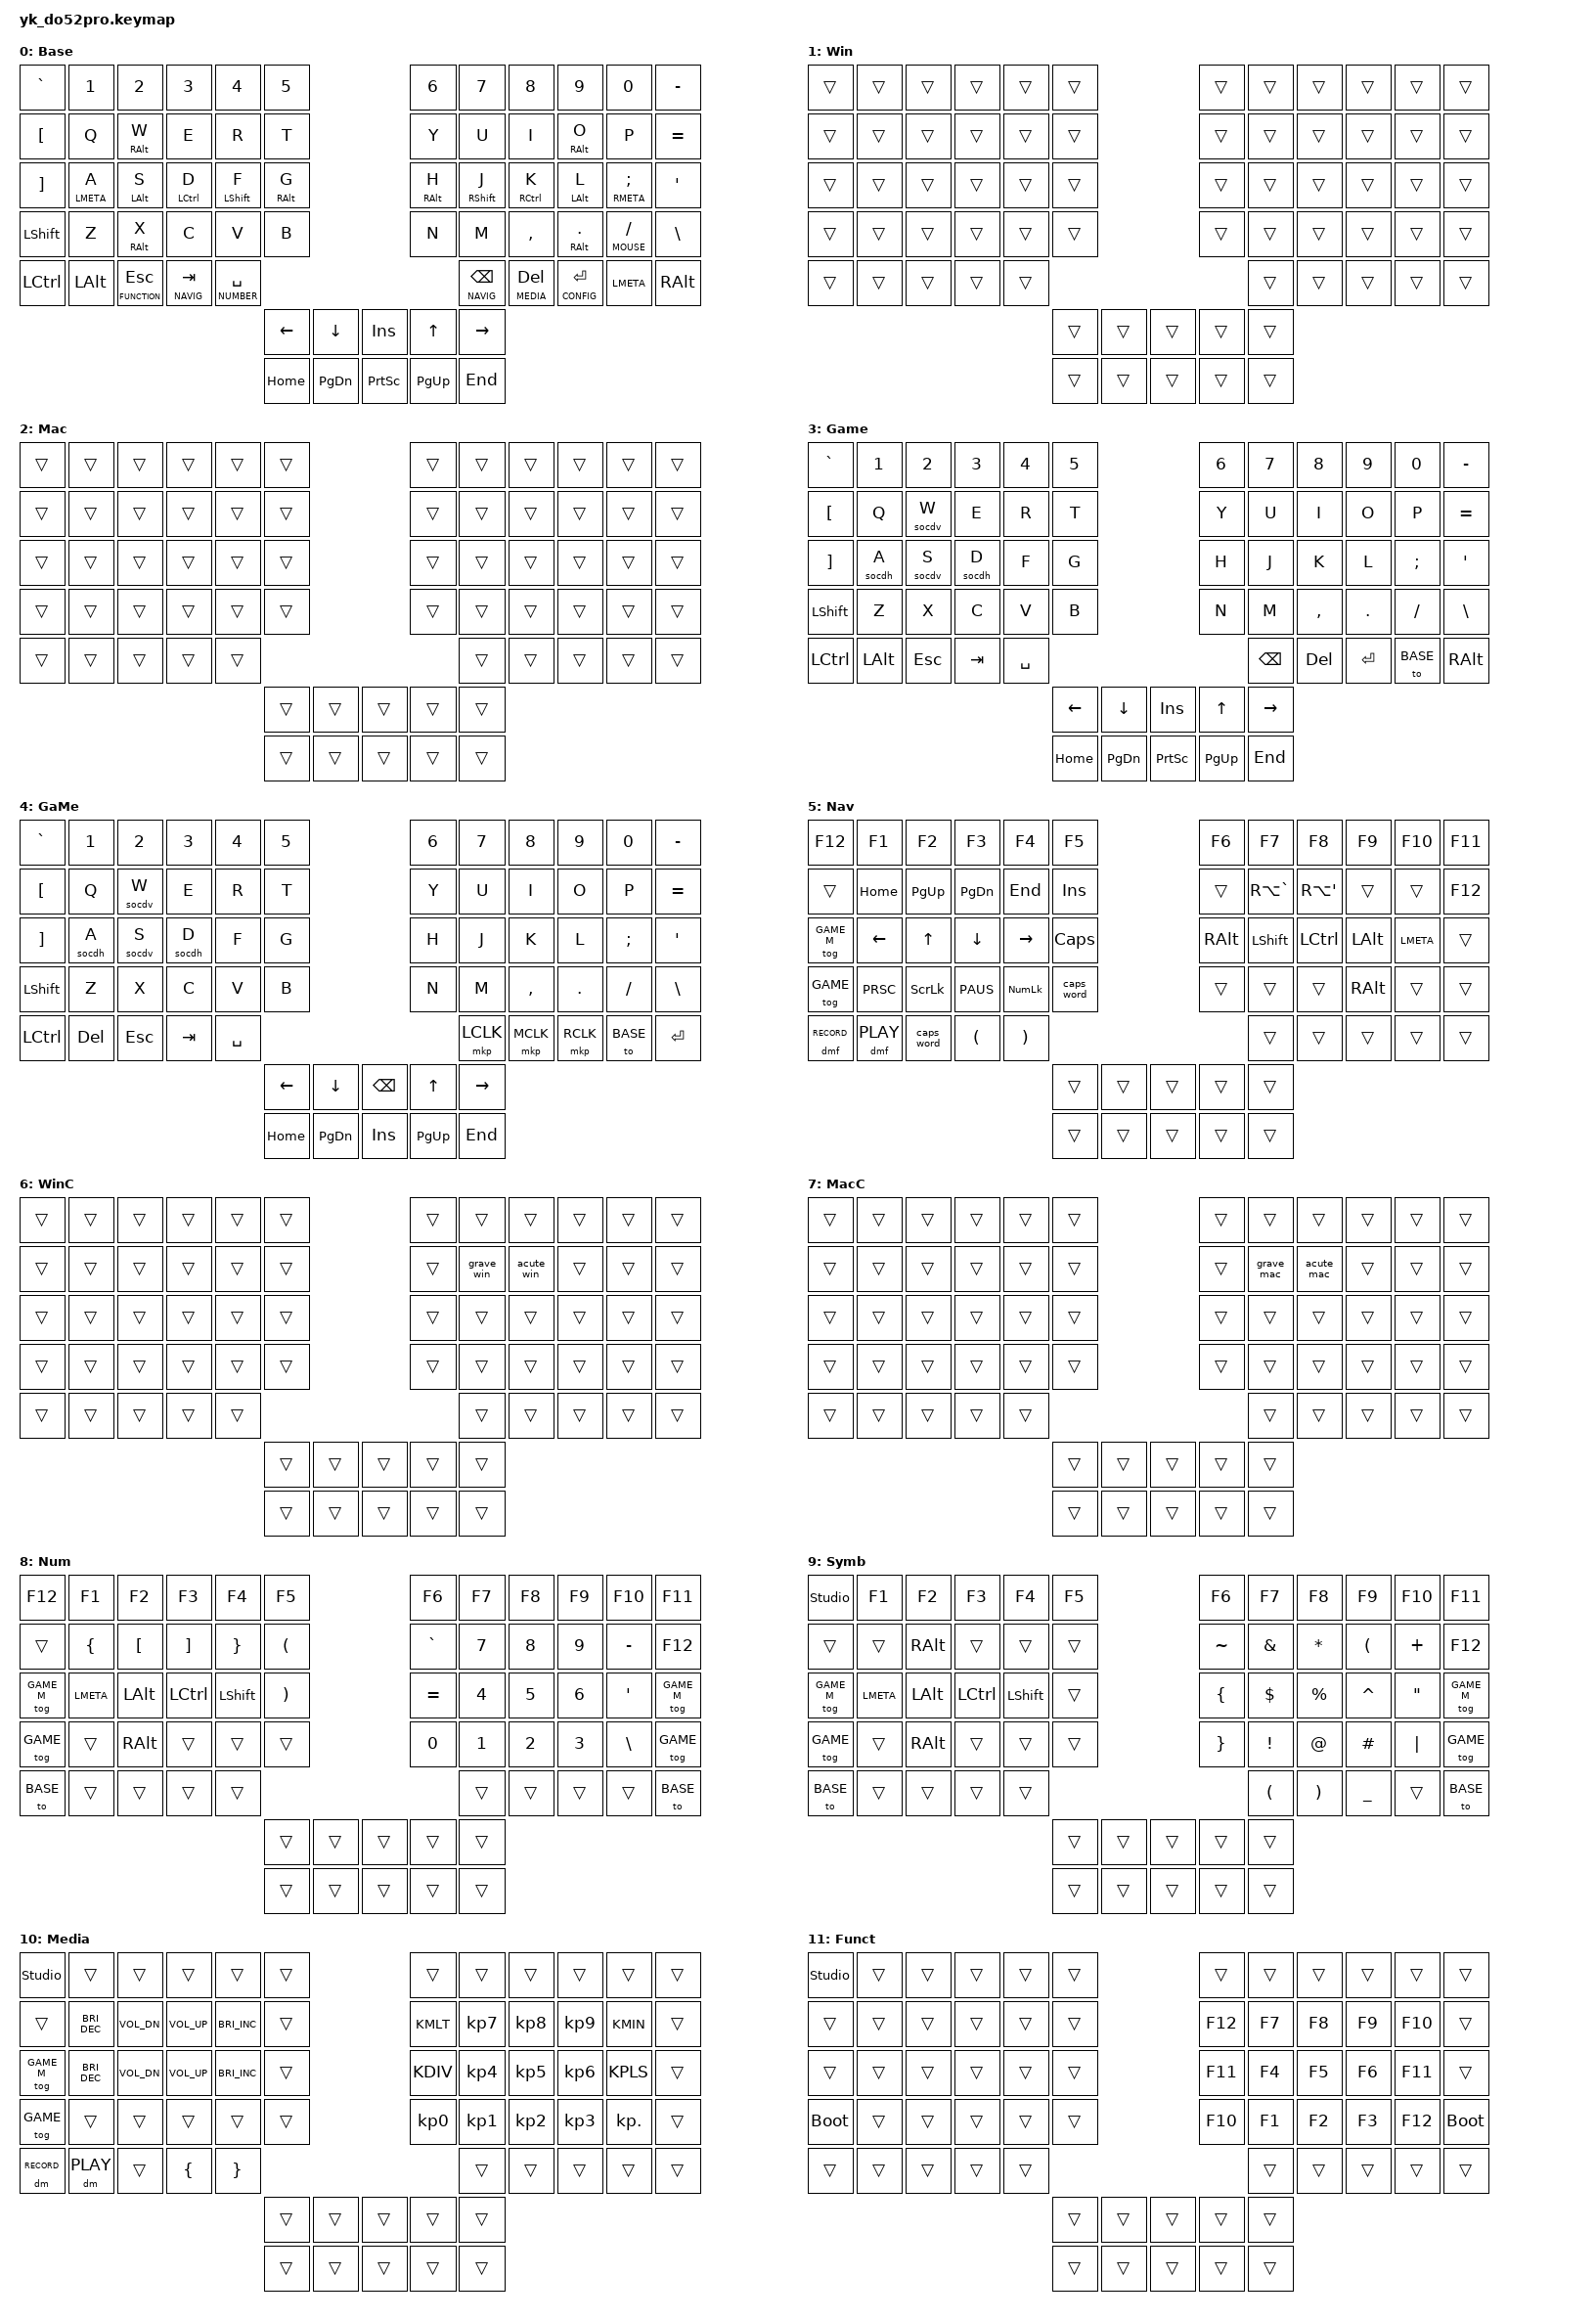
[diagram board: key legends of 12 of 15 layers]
/*
 * Copyright (c) 2020 The ZMK Contributors
 *
 * SPDX-License-Identifier: MIT
 */

#include <behaviors.dtsi>
#include <dt-bindings/zmk/keys.h>

//#include "zmk-helpers/helper.h"
#include "include/yk_do52_key.h"  
#include "include/hex_setup_macros.dtsi"                                     

#include <dt-bindings/zmk/bt.h>
#include <dt-bindings/zmk/ext_power.h>
#include <dt-bindings/zmk/outputs.h>

//#include <behaviors/battery_percentage_printer.dtsi>
#include <behaviors/socd.dtsi>
#include <dt-bindings/zmk/dynamic_macros.h>
#include "include/yk_do52pro_layers.dtsi"


/*
 * Defines to enable/disable features
 *
 * These defines allow us to conditionally enable and disable parts of the keymap config.
 *
 * For example, if we decide to build the firmware without the mouse features, we can
 * disable all the config options that rely on those forks and modules without having
 * to edit the entire keymap file manually every time.
 */

#define HAS_MOUSE_KEYS
#define HAS_MOUSE_TP

/ {
    conditional_layers {
        compatible = "zmk,conditional-layers";

        windows_accent {
            if-layers = <WIN NAVIG>;
            then-layer = <WINC>;
        };

        macos_accent {
            if-layers = <MAC NAVIG>;
            then-layer = <MACC>;
        };
    };
};


#ifdef HAS_MOUSE_KEYS
  #include <dt-bindings/zmk/mouse.h>
  #include <behaviors/mouse_keys.dtsi>
#endif  // HAS_MOUSE_KEYS

#ifdef HAS_MOUSE_TP
  // We store the trackpoint settings in a separate file
  // to make organization a little easier.
  #include "include/mouse_tp.dtsi"
#endif  // HAS_MOUSE_TP

// key-position labels
#define KEYS_L LT0 LT1 LT2 LT3 LT4 LM0 LM1 LM2 LM3 LM4 LB0 LB1 LB2 LB3 LB4  // left-hand keys
#define KEYS_R RT0 RT1 RT2 RT3 RT4 RM0 RM1 RM2 RM3 RM4 RB0 RB1 RB2 RB3 RB4  // right-hand keys
#define THUMBS LH4 LH3 LH2 LH1 LH0 RH0 RH1 RH2 RH3 RH4                      // thumb keys


// Adjust layer keys based on enabled features.
//
// This prevents build errors when we build the firmware
// without the mouse keys PR or the TP module.
#ifdef HAS_MOUSE_KEYS
  #define U_THUMB_INNER &mo MOUSE_KEYS
#else
  #define U_THUMB_INNER &none
#endif  // HAS_MOUSE_KEYS

#ifdef HAS_MOUSE_TP
  #define U_TOG_TP_SET &tog MOUSE_TP_SET
#else
  #define U_TOG_TP_SET &none
#endif  // HAS_MOUSE_TP


#define QUICK_TAP_MS 300 
#define TAPPING_TERM_MS 250
#define PRIOR_IDLE_MS 75
#define FLAVOUR "balanced"
// Disable line-wrap in your editor to see a "visualization" of the key layouts
/ {
   combos {
        compatible = "zmk,combos";
        combo_win {
            timeout-ms = <50>;
            key-positions = <56 14>; // SYS and W
            bindings = <&tog WIN>;
        };
        combo_mac {
            timeout-ms = <50>;
            key-positions = <56 43>; // SYS and M
            bindings = <&tog MAC>;
        };
        combo_set_win {
            timeout-ms = <50>;
            key-positions = <57 56 14>; // RALT SYS and W
            bindings = <&enable_hex_windows>;
        };
        combo_set_mac {
            timeout-ms = <50>;
            key-positions = <57 56 43>; // RALT SYS and M
            bindings = <&enable_hex_mac>;
        };
        combo_esc {
            timeout-ms = <50>;
            key-positions = <27 28>; // D and F
            bindings = <&kp ESC>;
        };
        combo_int {
            timeout-ms = <50>;
            key-positions = <25 26>; // A and S
            bindings = <&kp NON_US_BACKSLASH>;
        };
        combo_ret {
            timeout-ms = <50>;
            key-positions = <31 32>; // J and K
            bindings = <&kp KP_ENTER>;
        };
        combo_menu {
            timeout-ms = <50>;
            key-positions = <33 34>; // L and ;
            bindings = <&kp GUI>;
        };
    };
  
  behaviors {
       /* left-hand HRMs */
        hml: hml{
            compatible = "zmk,behavior-hold-tap";
            flavor = FLAVOUR;
            tapping-term-ms = <TAPPING_TERM_MS>;
            quick-tap-ms = <QUICK_TAP_MS>;                // repeat on tap-into-hold
            require-prior-idle-ms = <PRIOR_IDLE_MS>;
            #binding-cells = <2>;
            bindings = <&kp>, <&kp>;
            hold-trigger-key-positions = <KEYS_R>;
            hold-trigger-on-release;             // delay positional check until key-release
        };

        /* right-hand HRMs */
        hmr: hmr{
            compatible = "zmk,behavior-hold-tap";
            flavor = FLAVOUR;
            tapping-term-ms = <TAPPING_TERM_MS>;
            quick-tap-ms = <QUICK_TAP_MS>;                // repeat on tap-into-hold
            require-prior-idle-ms = <PRIOR_IDLE_MS>;
            #binding-cells = <2>;
            bindings = <&kp>, <&kp>;
            hold-trigger-key-positions = <KEYS_L>;
            hold-trigger-on-release;             // delay positional check until key-release
        };
        
        tl: tl{
            compatible = "zmk,behavior-hold-tap";
             flavor = "hold-preferred";
            tapping-term-ms = <TAPPING_TERM_MS>;
            quick-tap-ms = <QUICK_TAP_MS>;                // repeat on tap-into-hold
            require-prior-idle-ms = <PRIOR_IDLE_MS>;
            #binding-cells = <2>;
            bindings = <&mo>, <&kp>;
            hold-trigger-on-release;             // delay positional check until key-release
        };
        tl_e {
            compatible = "zmk,behavior-hold-tap";
            flavor = "hold-preferred";
            tapping-term-ms = <TAPPING_TERM_MS>;
            quick-tap-ms = <QUICK_TAP_MS>;                // repeat on tap-into-hold
            require-prior-idle-ms = <PRIOR_IDLE_MS>;
            #binding-cells = <2>;
            bindings = <&mo>, <&long_tap>;
            hold-trigger-on-release;             // delay positional check until key-release
        };              
    
        socdh: socdh{
            compatible = "zmk,behavior-socd";
            #binding-cells = <1>;
            bindings = <&kp>;
        };
        socdv: socdv{
            compatible = "zmk,behavior-socd";
            #binding-cells = <1>;
            bindings = <&kp>;
        };   
  };
  macros {
       grave_linux: grave_linux {
            compatible = "zmk,behavior-macro";
            #binding-cells = <0>;
            wait-ms = <30>;
            tap-ms = <30>;
            bindings =
                <&macro_press &kp LCTRL &kp LSHFT>,
                <&macro_tap &kp U>,
                <&macro_release &kp LSHFT &kp LCTRL>,
                <&macro_tap &kp N0 &kp N3 &kp N0 &kp N0 &kp ENTER>;
        };

        grave_win: grave_win {
            compatible = "zmk,behavior-macro";
            #binding-cells = <0>;
            wait-ms = <30>;
            tap-ms = <30>;
            bindings =
                <&macro_press &kp LALT>,
                <&macro_tap &kp KP_PLUS
                            &kp KP_N0 &kp KP_N3 &kp KP_N0 &kp KP_N0>,
                <&macro_release &kp LALT>;
        };

        grave_mac: grave_mac {
            compatible = "zmk,behavior-macro";
            #binding-cells = <0>;
            wait-ms = <30>;
            tap-ms = <30>;
            bindings =
                <&macro_press &kp LALT>,
                <&macro_tap &kp N0 &kp N3 &kp N0 &kp N0>,
                <&macro_release &kp LALT>;
        };

        acute_linux: acute_linux {
            compatible = "zmk,behavior-macro";
            #binding-cells = <0>;
            wait-ms = <30>;
            tap-ms = <30>;
            bindings =
                <&macro_press &kp LCTRL &kp LSHFT>,
                <&macro_tap &kp U>,
                <&macro_release &kp LSHFT &kp LCTRL>,
                <&macro_tap &kp N0 &kp N3 &kp N0 &kp N1 &kp ENTER>;
        };

        acute_win: acute_win {
            compatible = "zmk,behavior-macro";
            #binding-cells = <0>;
            wait-ms = <30>;
            tap-ms = <30>;
            bindings =
                <&macro_press &kp LALT>,
                <&macro_tap &kp KP_PLUS
                            &kp KP_N0 &kp KP_N3 &kp KP_N0 &kp KP_N1>,
                <&macro_release &kp LALT>;
        };

        acute_mac: acute_mac {
            compatible = "zmk,behavior-macro";
            #binding-cells = <0>;
            wait-ms = <30>;
            tap-ms = <30>;
            bindings =
                <&macro_press &kp LALT>,
                <&macro_tap &kp N0 &kp N3 &kp N0 &kp N1>,
                <&macro_release &kp LALT>;
        };
        

        long_tap: long_tap {
            compatible = "zmk,behavior-macro-one-param";
            #binding-cells = <1>;
            tap-ms = <80>;
            bindings = <&macro_param_1to1>, <&kp MACRO_PLACEHOLDER>;
        };
        dm: dm {
            compatible = "zmk,behavior-dynamic-macro";
            #binding-cells = <1>;
        };
        dmf: dmf {
            compatible = "zmk,behavior-dynamic-macro";
            #binding-cells = <1>;
            wait-ms = <20>;
        };
   };


  
  keymap {
    compatible = "zmk,keymap";
//0
    Base_layer {
      display-name = "Base";
      bindings = <
//|-----------------|-------------|-----------|------------|-----------------|----------------|---------------|   |---------------|---------------|-------------|------------|---------------|---------------|-------------|
   &kp GRAVE         &kp N1        &kp N2      &kp N3       &kp N4            &kp N5                                               &kp N6          &kp N7        &kp N8       &kp N9          &kp N0          &kp MINUS
   &kp LBKT          &kp Q         &hml RALT W &kp E        &kp R             &kp T                                                &kp Y           &kp U         &kp I        &hmr RALT O     &kp P           &kp EQUAL
   &kp RBKT          &hml LMETA A  &hml LALT S &hml LCTRL D &hml LSHIFT F     &hml RALT G                                          &hml RALT H     &hmr RSHIFT J &hmr RCTRL K &hmr LALT L     &hmr RMETA SEMI &kp SQT
   &kp LSHFT         &kp Z         &hml RALT X &kp C        &kp V             &kp B                                                &kp N           &kp M         &kp COMMA    &hmr RALT DOT   &tl MOUSE FSLH  &kp BSLH
   &kp LCTRL         &kp LALT                               &tl FUNCTION ESC  &tl NAVIG TAB    &tl NUMBER SPACE    &tl NAVIG BSPC  &tl MEDIA DEL   &tl CONFIG RET                             &kp LMETA       &kp RALT
                                                                           // DPAD |Left,    |Down,     |Middle,    |Up,       |Right
                                                                                    &kp LEFT  &kp DOWN   &kp INS     &kp UP     &kp RIGHT     //left                                                     
                                                                                    &kp HOME  &kp PG_DN  &kp PSCRN   &kp PG_UP  &kp END       //right
      >;
    };

 //1
     Windows_layer {
      display-name = "Win";
      bindings = <
//|------------|-------------|-----------|-----------|---------------|---------------|---------------|   |---------------|---------------|-------------|-----------|---------------|---------------|------------|
   &trans       &trans        &trans      &trans      &trans          &trans                                              &trans          &trans        &trans      &trans          &trans          &trans
   &trans       &trans        &trans      &trans      &trans          &trans                                              &trans          &trans        &trans      &trans          &trans          &trans
   &trans       &trans        &trans      &trans      &trans          &trans                                              &trans          &trans        &trans      &trans          &trans          &trans
   &trans       &trans        &trans      &trans      &trans          &trans                                              &trans          &trans        &trans      &trans          &trans          &trans
   &trans       &trans                                &trans          &trans          &trans               &trans         &trans          &trans                                    &trans          &trans 
                                                                           // DPAD |Left,    |Down,     |Middle,    |Up,       |Right
                                                                                    &trans    &trans     &trans      &trans     &trans        //left
                                                                                    &trans    &trans     &trans      &trans     &trans        //right                                                     
      >;
};

//2
     MacOS_layer {
      display-name = "Mac";
      bindings = <
//|------------|-------------|-----------|-----------|---------------|---------------|---------------|   |---------------|---------------|-------------|-----------|---------------|---------------|------------|
   &trans       &trans        &trans      &trans      &trans          &trans                                              &trans          &trans        &trans      &trans          &trans          &trans
   &trans       &trans        &trans      &trans      &trans          &trans                                              &trans          &trans        &trans      &trans          &trans          &trans
   &trans       &trans        &trans      &trans      &trans          &trans                                              &trans          &trans        &trans      &trans          &trans          &trans
   &trans       &trans        &trans      &trans      &trans          &trans                                              &trans          &trans        &trans      &trans          &trans          &trans
   &trans       &trans                                &trans          &trans          &trans               &trans     &trans          &trans                                    &trans          &trans 
                                                                           // DPAD |Left,    |Down,     |Middle,    |Up,       |Right
                                                                                    &trans    &trans     &trans      &trans     &trans        //left
                                                                                    &trans    &trans     &trans      &trans     &trans        //right                                                     
      >;
};

    
//3
      Game_layer {
      display-name = "Game";
      bindings = <
//|-----------------|-------------|-----------|------------|-----------------|----------------|--------------|   |---------------|---------------|-------------|-----------|-------------|---------------|------------|
   &kp GRAVE         &kp N1        &kp N2      &kp N3       &kp N4            &kp N5                                              &kp N6          &kp N7        &kp N8       &kp N9          &kp N0          &kp MINUS
   &kp LBKT          &kp Q         &socdv W    &kp E        &kp R             &kp T                                               &kp Y           &kp U         &kp I        &kp O           &kp P           &kp EQUAL
   &kp RBKT          &socdh A      &socdv S    &socdh D     &kp F             &kp G                                               &kp H           &kp J         &kp K        &kp L           &kp SEMI        &kp SQT
   &kp LSHFT         &kp Z         &kp X       &kp C        &kp V             &kp B                                               &kp N           &kp M         &kp COMMA    &kp DOT         &kp FSLH        &kp BSLH
   &kp LCTRL         &kp LALT                              &kp ESC           &kp TAB          &kp SPACE           &kp BSPC       &kp DEL         &kp RET                                     &to BASE        &kp RALT
                                                                          // DPAD |Left,    |Down,     |Middle,    |Up,       |Right
                                                                                    &kp LEFT  &kp DOWN   &kp INS     &kp UP     &kp RIGHT     //left                                                     
                                                                                    &kp HOME  &kp PG_DN  &kp PSCRN   &kp PG_UP  &kp END       //right
      >;
    };
//4
      GameMouse_layer {
      display-name = "GaMe";
      bindings = <
//|-----------------|-------------|-----------|------------|-----------------|----------------|--------------|   |---------------|---------------|-------------|-----------|-------------|---------------|------------|
   &kp GRAVE         &kp N1        &kp N2      &kp N3       &kp N4            &kp N5                                              &kp N6          &kp N7        &kp N8       &kp N9          &kp N0          &kp MINUS
   &kp LBKT          &kp Q         &socdv W    &kp E        &kp R             &kp T                                               &kp Y           &kp U         &kp I        &kp O           &kp P           &kp EQUAL
   &kp RBKT          &socdh A      &socdv S    &socdh D     &kp F             &kp G                                               &kp H           &kp J         &kp K        &kp L           &kp SEMI        &kp SQT
   &kp LSHFT         &kp Z         &kp X       &kp C        &kp V             &kp B                                               &kp N           &kp M         &kp COMMA    &kp DOT         &kp FSLH        &kp BSLH
   &kp LCTRL         &kp DEL                                &kp ESC           &kp TAB          &kp SPACE           &mkp LCLK      &mkp MCLK       &mkp RCLK                                  &to BASE        &kp RET
                                                                           // DPAD |Left,    |Down,     |Middle,    |Up,       |Right
                                                                                    &kp LEFT  &kp DOWN   &kp BSPC    &kp UP     &kp RIGHT     //left                                                     
                                                                                    &kp HOME  &kp PG_DN  &kp INS     &kp PG_UP  &kp END       //right
      >;
    };
//5
    Nav_layer {
      display-name = "Nav";
         bindings = <
//|------------|-------------|-----------|-----------|---------------|---------------|---------------|   |---------------|---------------|-------------|-----------|-------------|---------------|------------|
   &kp F12      &kp F1        &kp F2      &kp F3      &kp F4          &kp F5                                              &kp F6          &kp F7        &kp F8      &kp F9        &kp F10         &kp F11
   &trans       &kp HOME      &kp PG_UP   &kp PG_DN   &kp END         &kp INS                                             &trans          &kp RA(GRAVE) &kp RA(SQT) &trans        &trans          &kp F12
   &tog GAME_M  &kp LEFT      &kp UP      &kp DOWN    &kp RIGHT       &kp CAPS                                            &kp RALT        &kp LSHIFT    &kp LCTRL   &kp LALT      &kp LMETA       &trans
   &tog GAME    &kp PRSC      &kp SLCK    &kp PAUS    &kp KP_NUM      &caps_word                                          &trans          &trans        &trans      &kp RALT      &trans          &trans
   &dmf RECORD  &dmf PLAY                             &caps_word      &kp LPAR        &kp RPAR            &trans          &trans          &trans                                  &trans          &trans 
                                                                           // DPAD |Left,    |Down,     |Middle,    |Up,       |Right
                                                                                    &trans    &trans     &trans      &trans     &trans        //left
                                                                                    &trans    &trans     &trans      &trans     &trans        //right                                                     
      >;
    };

//6
     Windows_Accent {
      display-name = "WinC";
      bindings = <
//|------------|-------------|-----------|-----------|---------------|---------------|---------------|   |---------------|---------------|-------------|-----------|---------------|---------------|------------|
   &trans       &trans        &trans      &trans      &trans          &trans                                              &trans          &trans        &trans      &trans          &trans          &trans
   &trans       &trans        &trans      &trans      &trans          &trans                                              &trans          &grave_win    &acute_win  &trans          &trans          &trans
   &trans       &trans        &trans      &trans      &trans          &trans                                              &trans          &trans        &trans      &trans          &trans          &trans
   &trans       &trans        &trans      &trans      &trans          &trans                                              &trans          &trans        &trans      &trans          &trans          &trans
   &trans       &trans                                &trans          &trans          &trans               &trans         &trans          &trans                                    &trans          &trans 
                                                                           // DPAD |Left,    |Down,     |Middle,    |Up,       |Right
                                                                                    &trans    &trans     &trans      &trans     &trans        //left
                                                                                    &trans    &trans     &trans      &trans     &trans        //right                                                     
      >;
};

//7
     Mac_Accent {
      display-name = "MacC";
      bindings = <
//|------------|-------------|-----------|-----------|---------------|---------------|---------------|   |---------------|---------------|-------------|-----------|---------------|---------------|------------|
   &trans       &trans        &trans      &trans      &trans          &trans                                              &trans          &trans        &trans      &trans          &trans          &trans
   &trans       &trans        &trans      &trans      &trans          &trans                                              &trans          &grave_mac    &acute_mac  &trans          &trans          &trans
   &trans       &trans        &trans      &trans      &trans          &trans                                              &trans          &trans        &trans      &trans          &trans          &trans
   &trans       &trans        &trans      &trans      &trans          &trans                                              &trans          &trans        &trans      &trans          &trans          &trans
   &trans       &trans                                &trans          &trans          &trans               &trans         &trans          &trans                                    &trans          &trans 
                                                                           // DPAD |Left,    |Down,     |Middle,    |Up,       |Right
                                                                                    &trans    &trans     &trans      &trans     &trans        //left
                                                                                    &trans    &trans     &trans      &trans     &trans        //right                                                     
      >;
};


//8
    Num_layer {
      display-name = "Num";
        bindings = <
//|------------|-------------|-----------|-----------|---------------|---------------|---------------|   |---------------|---------------|-------------|-------------|-------------|---------------|------------|
   &kp F12      &kp F1        &kp F2      &kp F3      &kp F4          &kp F5                                              &kp F6          &kp F7        &kp F8        &kp F9        &kp F10         &kp F11         
   &trans       &kp LBRC      &kp LBKT    &kp RBKT    &kp RBRC        &kp LPAR                                            &kp GRAVE       &kp NUMBER_7  &kp NUMBER_8  &kp NUMBER_9  &kp MINUS       &kp F12
   &tog GAME_M  &kp LMETA     &kp LALT    &kp LCTRL   &kp LSHIFT      &kp RPAR                                            &kp EQUAL       &kp NUMBER_4  &kp NUMBER_5  &kp NUMBER_6  &kp SQT         &tog GAME_M
   &tog GAME    &trans        &kp RALT    &trans      &trans          &trans                                              &kp NUMBER_0    &kp NUMBER_1  &kp NUMBER_2  &kp NUMBER_3  &kp BSLH        &tog GAME
   &to BASE     &trans                                &trans          &trans          &trans               &trans         &trans          &trans                                    &trans          &to BASE
                                                                           // DPAD |Left,    |Down,     |Middle,    |Up,       |Right
                                                                                    &trans    &trans     &trans      &trans     &trans        //left
                                                                                    &trans    &trans     &trans      &trans     &trans        //right                                                     
      >;
    };

//9
    Symb_layer {
      display-name = "Symb";
          bindings = <
//|--------------|-------------|-----------|-----------|--------kks-------|---------------|---------------|   |---------------|---------------|-------------|-----------|-------------|---------------|------------|
   &studio_unlock &kp F1        &kp F2      &kp F3      &kp F4          &kp F5                                              &kp F6          &kp F7        &kp F8        &kp F9        &kp F10         &kp F11
   &trans         &trans        &kp RALT    &trans      &trans          &trans                                              &kp TILDE       &kp AMPERSAND &kp STAR      &kp LPAR      &kp PLUS        &kp F12
   &tog GAME_M    &kp LMETA     &kp LALT    &kp LCTRL   &kp LSHIFT      &trans                                              &kp LBRC        &kp DOLLAR    &kp PERCENT   &kp CARET     &kp DQT         &tog GAME_M
   &tog GAME      &trans        &kp RALT    &trans      &trans          &trans                                              &kp RBRC        &kp EXCL      &kp AT        &kp HASH      &kp PIPE        &tog GAME
   &to BASE       &trans                                &trans          &trans             &trans              &kp LPAR     &kp RPAR        &kp UNDER                                 &trans          &to BASE
                                                                           // DPAD |Left,    |Down,     |Middle,    |Up,       |Right
                                                                                    &trans    &trans     &trans      &trans     &trans        //left
                                                                                    &trans    &trans     &trans      &trans     &trans        //right                                                     
      >;
    };
//10
  Media_layer {
      display-name = "Media";
         bindings = <
//|--------------|-------------|-------------|-------------|---------------|---------------|---------------|   |---------------|---------------|-------------|-----------|-------------|---------------|------------|
   &studio_unlock &trans        &trans        &trans        &trans          &trans                                              &trans          &trans        &trans      &trans        &trans          &trans
  /*&bapp*/&trans &kp C_BRI_DEC &kp C_VOL_DN  &kp C_VOL_UP  &kp C_BRI_INC   &trans                                              &kp KMLT        &kp KP_N7     &kp KP_N8   &kp KP_N9     &kp KMIN        /*&bapp*/ &trans
   &tog GAME_M    &kp C_BRI_DEC &kp C_VOL_DN  &kp C_VOL_UP  &kp C_BRI_INC   &trans                                              &kp KDIV        &kp KP_N4     &kp KP_N5   &kp KP_N6     &kp KPLS        &trans
   &tog GAME      &trans        &trans        &trans        &trans          &trans                                              &kp KP_N0       &kp KP_N1     &kp KP_N2   &kp KP_N3     &kp KP_DOT      &trans
   &dm RECORD     &dm PLAY                                  &trans          &kp LBRC        &kp RBRC            &trans          &trans          &trans                                  &trans          &trans
                                                                           // DPAD |Left,    |Down,     |Middle,    |Up,       |Right
                                                                                    &trans    &trans     &trans      &trans     &trans        //left
                                                                                    &trans    &trans     &trans      &trans     &trans        //right                                                     
      >;
    };

//11
 Func_layer {
      display-name = "Funct";
      bindings = <
//|-----------------|-------------|-----------|-----------|---------------|---------------|---------------|   |---------------|---------------|-------------|-----------|-------------|---------------|------------|
   &studio_unlock    &trans        &trans      &trans      &trans          &trans                                              &trans          &trans        &trans      &trans        &trans          &trans
/*&bapp*/&trans      &trans        &trans      &trans      &trans          &trans                                              &kp F12         &kp F7        &kp F8      &kp F9        &kp F10         /*&bapp*/&trans
   &trans            &trans        &trans      &trans      &trans          &trans                                              &kp F11         &kp F4        &kp F5      &kp F6        &kp F11         &trans
   &bootloader       &trans        &trans      &trans      &trans          &trans                                              &kp F10         &kp F1        &kp F2      &kp F3        &kp F12         &bootloader
   &trans            &trans                                &trans          &trans          &trans              &trans          &trans          &trans                                  &trans          &trans 
                                                                           // DPAD |Left,    |Down,     |Middle,    |Up,       |Right
                                                                                    &trans    &trans     &trans      &trans     &trans        //left
                                                                                    &trans    &trans     &trans      &trans     &trans        //right                                                     
      >;
    };
//12
    Config_layer {
      display-name = "Confg";
      bindings = <
//|---------------|-------------|-----------|-----------|---------------|---------------|---------------|   |---------------|---------------|-------------|-------------|-------------|---------------|------------|
   &studio_unlock  &trans        &trans      &trans      &trans          &trans                                              &bt BT_SEL 0    &bt BT_SEL 1  &bt BT_SEL 2  &bt BT_SEL 3  &bt BT_SEL 4    &bt BT_SEL 5
   &trans          &trans        &trans      &trans      &trans          &trans                                              &bt BT_CLR      &bt BT_PRV    &out OUT_USB  &out OUT_BLE  &bt BT_NXT      &trans
   &sys_reset      &trans        &trans      &trans      &trans          &trans                                              &bt BT_CLR_ALL  &out OUT_TOG  &trans        &trans        &trans          &sys_reset
   &bootloader     &trans        &trans      &trans      &trans          &trans                                              &bt BT_DISC 0   &bt BT_DISC 1 &bt BT_DISC 2 &bt BT_DISC 3 &bt BT_DISC 4   &bootloader
   &trans          &trans                                &trans          &kp LBKT        &kp RBKT            &trans          &trans          &trans                                    &trans          &trans 
                                                                             // DPAD |Left,    |Down,     |Middle,    |Up,       |Right
                                                                                    &trans    &trans     &trans      &trans     &trans        //left
                                                                                    &trans    &trans     &trans      &trans     &trans        //right                                                     
      >;
    };

//13
     Mouse_layerAuto {
      display-name = "Mouse";
      bindings = <
//|------------|-------------|-----------|-----------|---------------|---------------|---------------|   |---------------|---------------|-------------|-----------|---------------|---------------|------------|
   &trans       &trans        &trans      &trans      &trans          &trans                                              &trans          &trans        &trans      &trans          &trans          &trans
   &trans       &trans        &trans      &trans      &trans          &trans                                              &trans          &trans        &trans      &mo SCROLL_TP   &none           &mo SCROLL_TP
   &trans       &trans        &trans      &trans      &trans          &trans                                              &trans          &trans        &trans      &trans          &trans          &mo SCROLL_TP
   &trans       &trans        &trans      &trans      &trans          &trans                                              &trans          &trans        &trans      &mo SCROLL_TP   &none           &mo SCROLL_TP
   &trans       &trans                                &trans          &trans          &trans               &mkp LCLK      &mkp MCLK       &mkp RCLK                                 &trans          &trans 
                                                                           // DPAD |Left,    |Down,     |Middle,    |Up,       |Right
                                                                                    &trans    &trans     &trans      &trans     &trans        //left
                                                                                    &trans    &trans     &trans      &trans     &trans        //right                                                     
      >;
       };

//14
     Scroll_layer {
      display-name = "Scroll";
      bindings = <
//|-------------|-------------|-----------|-----------|---------------|---------------|---------------|   |---------------|---------------|-------------|-----------|-------------|---------------|------------|
   &trans        &trans        &trans      &trans      &trans          &trans                                              &trans          &trans        &trans      &trans        &trans          &trans
   U_MSS_TP_S_I  &trans        &trans      &trans      &trans          &trans                                              &trans          &trans        &trans      &none         &mo MOUSE       &trans
   U_MSS_TP_S_D  &trans        &trans      &trans      &trans          &trans                                              &trans          &trans        &trans      &trans        &trans          &trans
   U_MSS_TP_V6_I &trans        &trans      &trans      &trans          &trans                                              &trans          &trans        &trans      &trans        &trans          &trans
   U_MSS_TP_V6_D &trans                                &trans          &trans          &trans               &mkp LCLK      &mkp MCLK       &mkp RCLK                               &trans          &trans 
                                                                           // DPAD |Left,    |Down,     |Middle,    |Up,       |Right
                                                                                    &trans    &trans     &trans      &trans     &trans        //left
                                                                                    &trans    &trans     &trans      &trans     &trans        //right                                                     
      >;
    };




#ifdef HAS_MOUSE_KEYS

#endif
#ifdef HAS_MOUSE_TP
//         // You can find the defines for the actual key press behaviors in `include/mouse_tp.dtsi`.
//         MouseSettings_layer {
//           display-name = "TP Set";
//           bindings = <
//     // ╭────────────────────────┬────────────────────────┬────────────────────────┬────────────────────────┬────────────────────────┬────────────────────────╮    ╭────────────────────────┬────────────────────────┬────────────────────────┬────────────────────────┬────────────────────────┬────────────────────────╮
//          U_TOG_TP_SET             U_TOG_TP_SET             &none                    U_MSS_TP_S_D             U_MSS_TP_S_I             U_MSS_TP_PT_I                 U_MSS_TP_PT_I            U_MSS_TP_S_D             U_MSS_TP_S_I             &none                    U_TOG_TP_SET              U_TOG_TP_SET
//     // ├────────────────────────┼────────────────────────┼────────────────────────┼────────────────────────┼────────────────────────┼────────────────────────┤    ├────────────────────────┼────────────────────────┼────────────────────────┼────────────────────────┼────────────────────────┼────────────────────────┤
//          U_MSS_RESET              U_MSS_RESET              &none                    U_MSS_TP_NI_D            U_MSS_TP_NI_I            U_MSS_TP_PT_D                 U_MSS_TP_PT_D            U_MSS_TP_NI_D            U_MSS_TP_NI_I            &none                    U_MSS_RESET               U_MSS_RESET
//     // ├────────────────────────┼────────────────────────┼────────────────────────┼────────────────────────┼────────────────────────┼────────────────────────┤    ├────────────────────────┼────────────────────────┼────────────────────────┼────────────────────────┼────────────────────────┼────────────────────────┤
//          U_MSS_LOG                U_MSS_LOG                &none                    U_MSS_TP_V6_D            U_MSS_TP_V6_I            &none                         &none                    U_MSS_TP_V6_D            U_MSS_TP_V6_I            &none                    U_MSS_LOG                 U_MSS_LOG
//     // ╰────────────────────────┴────────────────────────┴────────────────────────┴────────────────────────┼────────────────────────┼────────────────────────┤    ├────────────────────────┼────────────────────────┼────────────────────────┼────────────────────────┴────────────────────────┼────────────────────────╯
//                                                                                     &trans                   &mkp LCLK                &mkp RCLK                     &none                    &mkp LCLK                &mkp RCLK
//     //                                                                            ╰────────────────────────┴────────────────────────┴────────────────────────╯    ╰────────────────────────┴────────────────────────┴────────────────────────╯
//           >;
//         };


#endif

 

  };
};









































